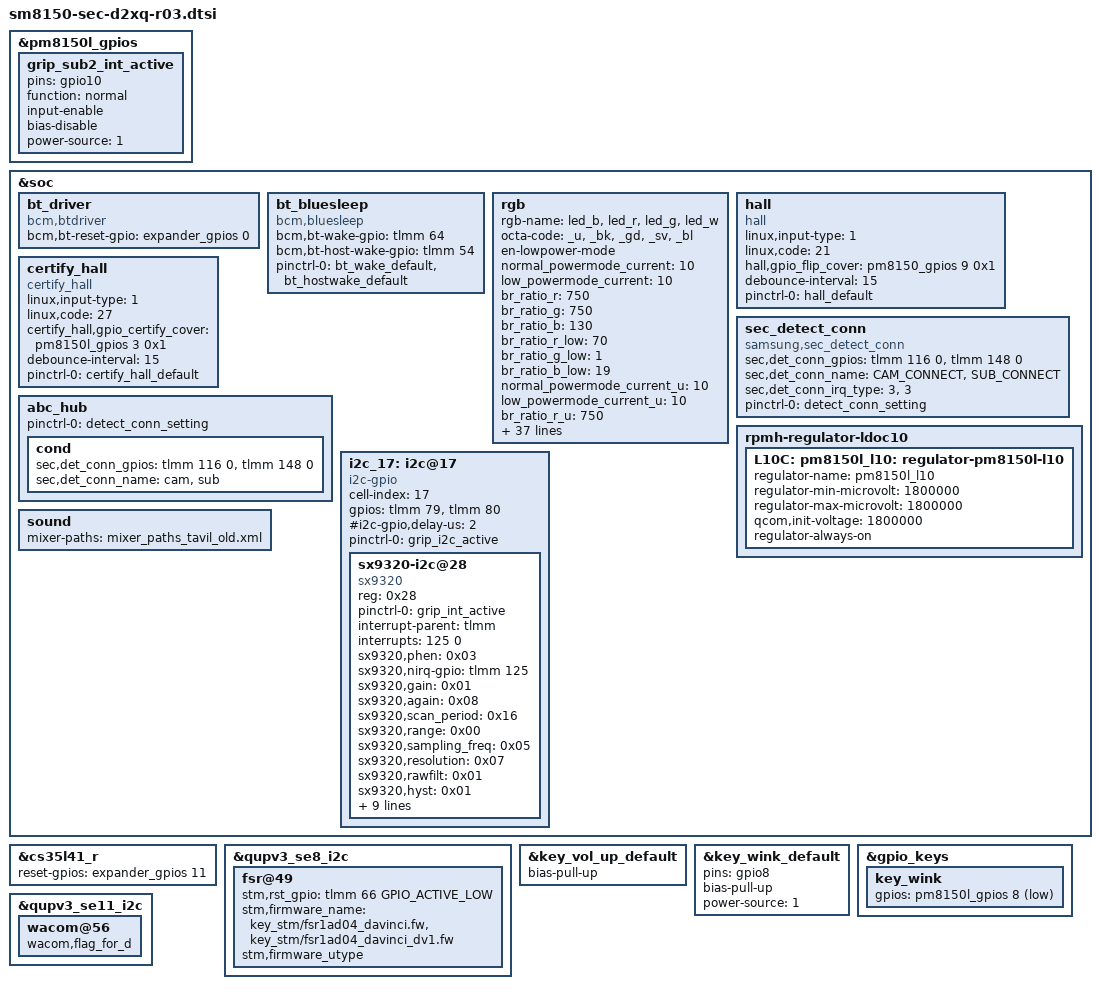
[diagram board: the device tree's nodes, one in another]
/* Copyright (c) 2016-2017, The Linux Foundation. All rights reserved.
 *
 * This program is free software; you can redistribute it and/or modify
 * it under the terms of the GNU General Public License version 2 and
 * only version 2 as published by the Free Software Foundation.
 *
 * This program is distributed in the hope that it will be useful,
 * but WITHOUT ANY WARRANTY; without even the implied warranty of
 * MERCHANTABILITY or FITNESS FOR A PARTICULAR PURPOSE.  See the
 * GNU General Public License for more details.
 */

#include "sm8150-sec-d2xq-common.dtsi"
#include "sm8150-sec-d2xq-optics-r00.dtsi"

&pm8150l_gpios {
	grip_sub2_int_active: grip_sub2_int_active {
		pins = "gpio10";
		function = "normal";
		input-enable;
		bias-disable;
		power-source = <1>;
	};
};	

&soc {
	bt_driver {
		compatible = "bcm,btdriver";  //bt_en
		pinctrl-names = "default";
		bcm,bt-reset-gpio = <&expander_gpios 0 GPIO_ACTIVE_HIGH>;
		status = "okay";
	};

	bt_bluesleep {
		compatible = "bcm,bluesleep";
		bcm,bt-wake-gpio = <&tlmm 64 0>;
		bcm,bt-host-wake-gpio = <&tlmm 54 0>;
		pinctrl-names = "default";
		pinctrl-0 = <&bt_wake_default &bt_hostwake_default>;
		status = "okay";
	};

	rgb {
		device_type = "star1";
		rgb-name = "led_b", "led_r", "led_g", "led_w";
		octa-code = "_u", "_bk", "_gd", "_sv", "_bl";

		en-lowpower-mode;

		normal_powermode_current = <10>;
		low_powermode_current = <10>;
		br_ratio_r = <750>;
		br_ratio_g = <750>;
		br_ratio_b = <130>;
		br_ratio_r_low = <70>;
		br_ratio_g_low = <1>;
		br_ratio_b_low = <19>;

		normal_powermode_current_u = <10>;
		low_powermode_current_u = <10>;
		br_ratio_r_u = <750>;
		br_ratio_g_u = <750>;
		br_ratio_b_u = <130>;
		br_ratio_r_low_u = <70>;
		br_ratio_g_low_u = <1>;
		br_ratio_b_low_u = <19>;

		normal_powermode_current_bk = <10>;
		low_powermode_current_bk = <10>;
		br_ratio_r_bk = <750>;
		br_ratio_g_bk = <70>;
		br_ratio_b_bk = <130>;
		br_ratio_r_low_bk = <70>;
		br_ratio_g_low_bk = <1>;
		br_ratio_b_low_bk = <19>;

		normal_powermode_current_gd = <10>;
		low_powermode_current_gd = <10>;
		br_ratio_r_gd = <750>;
		br_ratio_g_gd = <70>;
		br_ratio_b_gd = <130>;
		br_ratio_r_low_gd = <70>;
		br_ratio_g_low_gd = <1>;
		br_ratio_b_low_gd = <19>;

		normal_powermode_current_sv = <10>;
		low_powermode_current_sv = <10>;
		br_ratio_r_sv = <750>;
		br_ratio_g_sv = <70>;
		br_ratio_b_sv = <130>;
		br_ratio_r_low_sv = <70>;
		br_ratio_g_low_sv = <1>;
		br_ratio_b_low_sv = <19>;

		normal_powermode_current_bl = <10>;
		low_powermode_current_bl = <10>;
		br_ratio_r_bl = <750>;
		br_ratio_g_bl = <70>;
		br_ratio_b_bl = <130>;
		br_ratio_r_low_bl = <70>;
		br_ratio_g_low_bl = <1>;
		br_ratio_b_low_bl = <19>;
	};

	hall {
                status = "okay";
                compatible = "hall";
                linux,input-type = <1>;
                linux,code = <21>;
                hall,gpio_flip_cover = <&pm8150_gpios 9 0x1>;
                debounce-interval = <15>;
		pinctrl-names = "default";
	        pinctrl-0 = <&hall_default>;
        };

        certify_hall {
		status = "okay";
                compatible = "certify_hall";
                linux,input-type = <1>;
                linux,code = <27>;
                certify_hall,gpio_certify_cover = <&pm8150l_gpios 3 0x1>;
                debounce-interval = <15>;
		pinctrl-names = "default";
	        pinctrl-0 = <&certify_hall_default>;
        };

	sec_detect_conn {
		compatible = "samsung,sec_detect_conn";
		sec,det_conn_gpios = <&tlmm 116 0 /* CAM_DETECT */
					&tlmm 148 0>; /* SUB_DETECT */

		sec,det_conn_name = "CAM_CONNECT", "SUB_CONNECT";

		sec,det_conn_irq_type = <3>, /* CAM_DETECT FALLING, RIGING EDGE*/
					<3>; /* SUB_DETECT FALLING, RIGING EDGE*/

		pinctrl-names = "det_ap_connect";
		pinctrl-0 = <&detect_conn_setting>;
	};

	abc_hub {
		pinctrl-names = "det_ap_connect";
		pinctrl-0 = <&detect_conn_setting>;

		cond {
			sec,det_conn_gpios = <&tlmm 116 0 /* CAM_DETECT */
						&tlmm 148 0>; /* SUB_DETECT */
			sec,det_conn_name = "cam", "sub";
		};
	};

	/* VDD_GRIP_1P8 */
	rpmh-regulator-ldoc10 {
		L10C: pm8150l_l10: regulator-pm8150l-l10 {
			regulator-name = "pm8150l_l10";
			regulator-min-microvolt = <1800000>;
			regulator-max-microvolt = <1800000>;
			qcom,init-voltage = <1800000>;
			regulator-always-on;
		};
	};

	i2c_17: i2c@17 { /* SW I2C */
		status = "ok";

		cell-index = <17>;
		compatible = "i2c-gpio";
		gpios = <&tlmm 79 0 /* sda */
			 &tlmm 80 0 /* scl */
		>;
		#i2c-gpio,delay-us = <2>;
		#address-cells = <1>;
		#size-cells = <0>;
		pinctrl-names = "default";
		pinctrl-0 = <&grip_i2c_active>;

		sx9320-i2c@28 {
			compatible = "sx9320";
			reg = <0x28>;
			status = "okay";
			pinctrl-names = "default";
			pinctrl-0 = <&grip_int_active>;

			interrupt-parent = <&tlmm>;
			interrupts = <125 0>;

			/* only phase 3 enable */
			sx9320,phen = <0x03>;
			sx9320,nirq-gpio = <&tlmm 125 0>;
			sx9320,gain = <0x01>;
			sx9320,again = <0x08>;
			sx9320,scan_period = <0x16>;
			sx9320,range = <0x00>;
			sx9320,sampling_freq = <0x05>;
			sx9320,resolution = <0x07>;
			sx9320,rawfilt = <0x01>;
			sx9320,hyst = <0x01>;
			sx9320,avgposfilt = <0x04>;
			sx9320,avgnegfilt = <0x01>;
			sx9320,avgthresh = <0x20>;
			sx9320,debouncer = <0x01>;
			sx9320,normal_thd = <0x13>;
			sx9320,afeph0 = <0x0>;
			sx9320,afeph1 = <0x0>;
			sx9320,afeph2 = <0x0>;
			sx9320,afeph3 = <0x4>;
		};
	};

	sound {
		mixer-paths = "mixer_paths_tavil_old.xml";
	};
};

&cs35l41_r {
	reset-gpios = <&expander_gpios 11 0>;
};

&qupv3_se8_i2c { /* keyless */
	fsr@49 {
		stm,rst_gpio = <&tlmm 66 GPIO_ACTIVE_LOW>;
		stm,firmware_name = "key_stm/fsr1ad04_davinci.fw", "key_stm/fsr1ad04_davinci_dv1.fw";
		stm,firmware_utype;
	};
};

&key_vol_up_default {
	/delete-property/ bias-disable;
	bias-pull-up;
};

&key_wink_default {
	pins = "gpio8";
	/delete-property/ bias-disable;
	bias-pull-up;
	power-source = <1>;
};

&gpio_keys {
	key_wink {
		gpios = <&pm8150l_gpios 8 GPIO_ACTIVE_LOW>;
	};
};

&qupv3_se11_i2c {
	wacom@56 {
		wacom,flag_for_d; /* VDDL of wacom is made leakage about DISP_TE.
				   * before modification of schematics about VDDL,
				   * use this property only D model less than hw rev 04.
				   */
	};
};
